# CMSDK_CM4_FP register map
Vendor: ARM Ltd.; Series: ARM Cortex M4; File version: 1.0
ARM 32-bit Cortex-M4 based device
CPU: CM4 r0p1, little endian, MPU, FPU, 3 interrupt priority bits
Registers are 32-bit, read-write, reset 0x0 unless marked. A register's access mark holds for its fields unless they carry their own. Offsets are from the block's base; lines under a group give offsets from that group; [hi:lo] are bit positions; {n}, {i} and the like mark numbered series; 'fields as' and 'values as' point back to an identical list; <NAME> marks a mode.

## Memory map
0x40000000 TIMER0 size 0x10
0x40001000 TIMER1 size 0x10
0x40002000 DUALTIMER size 0x3C
0x40004000 UART0 size 0x14
0x40005000 UART1 size 0x14
0x40006000 UART2 size 0x14
0x40007000 UART3 size 0x14
0x40008000 WDT size 0xC04 — Watchdog Timer
0x40009000 UART4 size 0x14
0x40010000 GPIO0 size 0x3C — general-purpose I/O
0x40011000 GPIO1 size 0x3C
0x40012000 GPIO2 size 0x3C
0x40013000 GPIO3 size 0x3C
0x40027000 SPI size 0x40
0x40028000 FPGAIO size 0x100 — FPGA System Control I/O
0x4002F000 SCC size 0x1000 — Serial Communication Controller

## Interrupts
0 UART0_RX (UART0) — UART 0 RX interrupt
0 WDT — Watchdog interrupt
2 UART1_RX (UART1) — UART 1 RX interrupt
4 UART2_RX (UART2) — UART 2 RX interrupt
6 GPIO0 — GPIO 0 combined interrupt
7 GPIO1 — GPIO 1 combined interrupt
8 TIMER0 — Timer 0 interrupt
9 TIMER1 — Timer 1 interrupt
10 DUALTIMER — Dual Timer interrupt
11 SPI — Combined SPI 0, SPI 1 interrupt
16 GPIO2 — GPIO 2 combined interrupt
17 GPIO3 — GPIO 3 combined interrupt
18 UART3_RX (UART3) — UART 3 RX Interrupt
20 UART4_RX (UART4) — UART 4 RX interrupt

## TIMER0
Base 0x40000000
Same registers: TIMER1 0x40001000
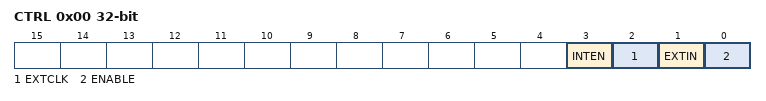
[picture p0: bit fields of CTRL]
0x00 CTRL — Control Register
  [3] INTEN — Interrupt Enable
    0=Disable (Interrupt is disabled); 1=Enable (Interrupt is enabled)
  [2] EXTCLK — External Clock Enable
    0=Disable (External Clock s disabled); 1=Enable (External Clock is enabled)
  [1] EXTIN — External Input as Enable
    0=Disable (External Input as Enable is disabled); 1=Enable (External Input as Enable is enabled)
  [0] ENABLE
    0=Disable (Timer is disabled); 1=Enable (Timer is enabled)
0x04 VALUE — Current Timer Counter Value
0x08 RELOAD — Counter Reload Value
0x0C INTSTATUS ro — Timer Interrupt status register
0x0C INTCLEAR wo write-1-clears (alternate view of INTSTATUS) — Timer Interrupt clear register

## DUALTIMER
Base 0x40002000
0x00 TIMER1LOAD
0x04 TIMER1VALUE ro reset 0xFFFFFFFF
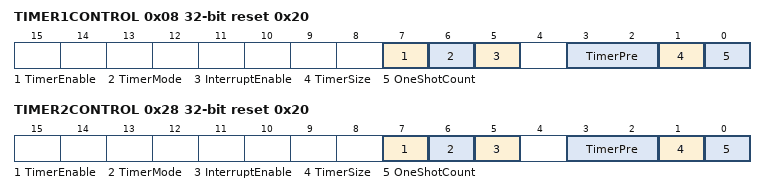
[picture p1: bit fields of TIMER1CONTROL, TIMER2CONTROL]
0x08 TIMER1CONTROL reset 0x20
  [7] TimerEnable — Timer Enable Enable bit.
    0=Disable (Timer is disabled.); 1=Enable (Timer is enabled.)
  [6] TimerMode — Timer Mode bit.
    0=Free-Running timer mode; 1=Periodic timer mode
  [5] InterruptEnable — Interrupt Enable bit.
    0=Disable (Interrupt is disabled.); 1=Enable (Interrupt is enabled.)
  [3:2] TimerPre — Timer prescale bits.
    0=divided by 1 (clock is divided by 1); 1=divided by 16 (clock is divided by 16); 2=divided by 256 (clock is divided by 256)
  [1] TimerSize — Selects 16-bit or 32- bit counter operation.
    0=16-bit counter mode; 1=32-bit counter mode
  [0] OneShotCount — Selects one-shot or wrapping counter mode.
    0=Wrapping counter mode; 1=One-shot counter mode
0x0C TIMER1INTCLR wo — Timer 1 Interrupt Clear Register
  [0] INT write-1-clears — Interrupt
0x10 TIMER1RIS ro — Timer 1 Raw Interrupt Status Register
  [0] RIS — Raw Timer interrupt
0x14 TIMER1MIS ro — Timer 1 Mask Interrupt Status Register
  [0] MIS — Masked Timer interrupt
0x18 TIMER1BGLOAD — Timer 1 Background Load Register
0x20 TIMER2LOAD
0x24 TIMER2VALUE ro reset 0xFFFFFFFF
0x28 TIMER2CONTROL reset 0x20
  fields as TIMER1CONTROL
0x2C TIMER2INTCLR wo — Timer 2 Interrupt Clear Register
  [0] INT write-1-clears — Interrupt
0x30 TIMER2RIS ro — Timer 2 Raw Interrupt Status Register
  [0] RIS — Raw Timer interrupt
0x34 TIMER2MIS ro — Timer 2 Mask Interrupt Status Register
  [0] MIS — Masked Timer interrupt
0x38 TIMER2BGLOAD — Timer 2 Background Load Register

## Licence text in the file
ARM Limited (ARM) is supplying this software for use with Cortex-M processor based microcontroller, but can be equally used for other suitable processor architectures. This file can be freely distributed. Modifications to this file shall be clearly marked. . THIS SOFTWARE IS PROVIDED "AS IS". NO WARRANTIES, WHETHER EXPRESS, IMPLIED. OR STATUTORY, INCLUDING, BUT NOT LIMITED TO, IMPLIED WARRANTIES OF. MERCHANTABILITY AND FITNESS FOR A PARTICULAR PURPOSE APPLY TO THIS SOFTWARE. ARM SHALL NOT, IN ANY CIRCUMSTANCES, BE LIABLE FOR SPECIAL, INCIDENTAL, OR. CONSEQUENTIAL DAMAGES, FOR ANY REASON WHATSOEVER.

## Notices in the file
Copyright (C) 2012-2017 ARM Limited. All rights reserved.
Purpose: System Viewer Description (SVD) Example (Schema Version 1.1)
This is a description of a none-existent and incomplete device
for demonstration purposes only.
Redistribution and use in source and binary forms, with or without
modification, are permitted provided that the following conditions are met:
- Redistributions of source code must retain the above copyright
notice, this list of conditions and the following disclaimer.
- Redistributions in binary form must reproduce the above copyright
notice, this list of conditions and the following disclaimer in the
documentation and/or other materials provided with the distribution.
- Neither the name of ARM nor the names of its contributors may be used
to endorse or promote products derived from this software without
specific prior written permission.
THIS SOFTWARE IS PROVIDED BY THE COPYRIGHT HOLDERS AND CONTRIBUTORS "AS IS"
AND ANY EXPRESS OR IMPLIED WARRANTIES, INCLUDING, BUT NOT LIMITED TO, THE
ARE DISCLAIMED. IN NO EVENT SHALL COPYRIGHT HOLDERS AND CONTRIBUTORS BE
LIABLE FOR ANY DIRECT, INDIRECT, INCIDENTAL, SPECIAL, EXEMPLARY, OR
CONSEQUENTIAL DAMAGES (INCLUDING, BUT NOT LIMITED TO, PROCUREMENT OF
SUBSTITUTE GOODS OR SERVICES; LOSS OF USE, DATA, OR PROFITS; OR BUSINESS
INTERRUPTION) HOWEVER CAUSED AND ON ANY THEORY OF LIABILITY, WHETHER IN
CONTRACT, STRICT LIABILITY, OR TORT (INCLUDING NEGLIGENCE OR OTHERWISE)
ARISING IN ANY WAY OUT OF THE USE OF THIS SOFTWARE, EVEN IF ADVISED OF THE
POSSIBILITY OF SUCH DAMAGE.
